VERSION ""

NS_ :

BS_:

BU_: HCU XXX

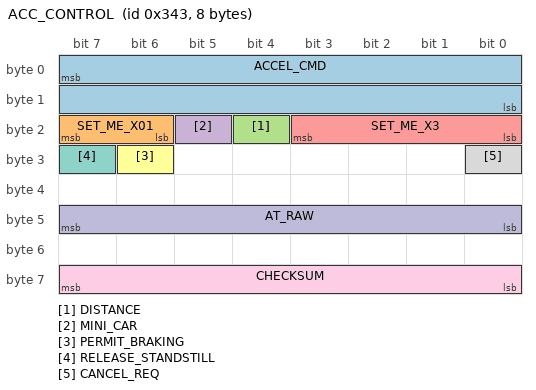
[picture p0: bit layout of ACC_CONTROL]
BO_ 835 ACC_CONTROL: 8 DSU
 SG_ ACCEL_CMD : 7|16@0- (0.001,0) [-20|20] "m/s2" HCU
 SG_ SET_ME_X01 : 23|2@0+ (1,0) [0|3] "" HCU
 SG_ DISTANCE : 20|1@0+ (1,0) [0|1] "" XXX
 SG_ MINI_CAR : 21|1@0+ (1,0) [0|1] "" XXX
 SG_ SET_ME_X3 : 19|4@0+ (1,0) [0|15] "" XXX
 SG_ PERMIT_BRAKING : 30|1@0+ (1,0) [0|1] "" HCU
 SG_ RELEASE_STANDSTILL : 31|1@0+ (1,0) [0|1] "" HCU
 SG_ CANCEL_REQ : 24|1@0+ (1,0) [0|1] "" HCU
 SG_ CHECKSUM : 63|8@0+ (1,0) [0|255] "" XXX
 SG_ AT_RAW : 47|8@0- (0.05,0) [0|255] "m/s^2" XXX

CM_ SG_ 835 AT_RAW "Possible used for engine brake";
